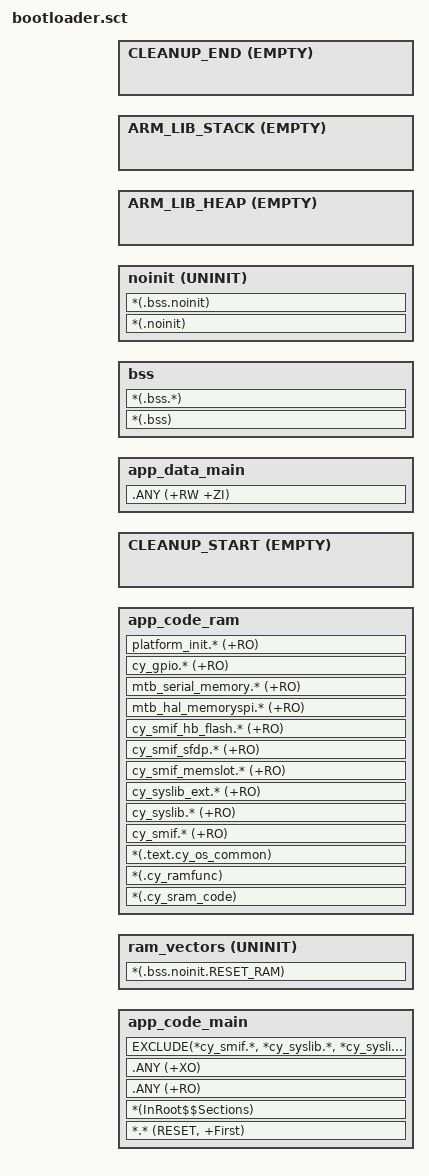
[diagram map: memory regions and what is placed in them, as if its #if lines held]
#! armclang -E --target=arm-arm-none-eabi -mcpu=cortex-m33 -xc
; command above MUST be in first line (no comment above!)
/***************************************************************************/ 






































/* Include the device memory definitions generated by the Device Configurator */
#include "../../config/GeneratedSource/cymem_armlink_CM33_0_S.sct"

/* Define the stack size for the application */
/* To set stack size in application add makefile ldflags: --predefine="-DAPP_MSP_STACK_SIZE=<CUSTOM_VALUE>" */
#ifdef APP_MSP_STACK_SIZE
#define __STACK_SIZE    APP_MSP_STACK_SIZE
#else
#define __STACK_SIZE    0x00002000
#endif

/* User Stack & Heap boundary definition */
/* Place the top of the stack at the end of the m33s_data_S */
#define __STACK_TOP    (CYMEM_CM33_0_S_m33s_data_S_START + CYMEM_CM33_0_S_m33s_data_SIZE)
/* Position the beginning of the heap right after the noinit ER, ensuring an 8-byte alignment */
#define __HEAP_BASE    AlignExpr(ImageLimit(noinit), 8)
/* The heap extends to the stack */
#define __HEAP_SIZE    (__STACK_TOP - __STACK_SIZE - __HEAP_BASE)

/* Device definitions */
#define VECTORS_ALIGNMENT 0x400

/* The size of the MCU boot header area at the start of main code region */
#define MCUBOOT_HEADER_SIZE  0x400

/* The size of the signature trail area at the end of main code region */
#define SIGNATURE_TRAIL_SIZE 0x400


/* Serial Memory Interface block #0 memory #1, 16 MB */
/* Start address is offset by MCUBOOT_HEADER_SIZE to let the area free for the MCU boot header */
LR_XIP_PORT0 (CYMEM_CM33_0_S_bootloader_nvm_sel_S_START + MCUBOOT_HEADER_SIZE) (CYMEM_CM33_0_S_bootloader_nvm_SIZE - MCUBOOT_HEADER_SIZE - SIGNATURE_TRAIL_SIZE)
{
  /* The execution region is designated for the main secure (S) application code for the Cortex-M33 */
  /* Performance-sensitive or critical functions that need to be executed in sram are manually excluded */
  app_code_main (CYMEM_CM33_0_S_bootloader_nvm_sel_S_START + MCUBOOT_HEADER_SIZE) ALIGN VECTORS_ALIGNMENT (CYMEM_CM33_0_S_bootloader_nvm_SIZE - MCUBOOT_HEADER_SIZE)
  {
    *.* (RESET, +First)
    *(InRoot$$Sections)
    .ANY (+RO)
    .ANY (+XO)
    EXCLUDE(*cy_smif.*, *cy_syslib.*, *cy_syslib_ext.*, *cy_smif_memslot.*, *cy_smif_sfdp.*, *cy_smif_hb_flash.*, *mtb_hal_memoryspi.*, *mtb_serial_memory.*, *cy_gpio.*, *platform_init.* )
  }

  /* A region for the vector table */
  ram_vectors AlignExpr(CYMEM_CM33_0_S_m33s_data_S_START, VECTORS_ALIGNMENT) ALIGN VECTORS_ALIGNMENT UNINIT CYMEM_CM33_0_S_m33s_data_SIZE
  {
    *(.bss.noinit.RESET_RAM)
  }

  /* The execution region for performance-sensitive or critical functions that need to be executed in SRAM */
  app_code_ram AlignExpr(ImageLimit(ram_vectors), 8) ALIGN 8 CYMEM_CM33_0_S_m33s_data_SIZE
  {
    *(.cy_sram_code)
    *(.cy_ramfunc)
    *(.text.cy_os_common)
    cy_smif.* (+RO)
    cy_syslib.* (+RO)
    cy_syslib_ext.* (+RO)
    cy_smif_memslot.* (+RO)
    cy_smif_sfdp.* (+RO)
    cy_smif_hb_flash.* (+RO)
    mtb_hal_memoryspi.* (+RO)
    mtb_serial_memory.* (+RO)
    cy_gpio.* (+RO)
    platform_init.* (+RO)
  }

  /* This empty, zero long execution region is here to mark the start address of cleanup region */
  CLEANUP_START AlignExpr(ImageLimit(app_code_ram), 4) ALIGN 4 EMPTY 0x0 {}

  /* The execution region for initialized data memory */
  app_data_main AlignExpr(ImageLimit(app_code_ram), 4) ALIGN 4 CYMEM_CM33_0_S_m33s_data_SIZE
  {
    .ANY (+RW +ZI)
  }
}

/* SRAM, 1 MB */
/* Note. This load region must not contain any loadable data; only UNINIT or BSS execution regions are allowed */
LR_SRAM CYMEM_CM33_0_S_m33s_data_S_START CYMEM_CM33_0_S_m33s_data_SIZE
{

  /* A section for non-initialized data memory */
  bss AlignExpr(ImageLimit(app_data_main), 8) ALIGN 8 (CYMEM_CM33_0_S_m33s_data_SIZE - AlignExpr(ImageLength(ram_vectors), VECTORS_ALIGNMENT) - AlignExpr(ImageLength(app_data_main), 4))
  {
    *(.bss)
    *(.bss.*)
  }

  /* A region for variables that should not be initialized during the device startup */
  noinit AlignExpr(ImageLimit(bss), 4) ALIGN 4 UNINIT (CYMEM_CM33_0_S_m33s_data_SIZE - AlignExpr(ImageLength(ram_vectors), VECTORS_ALIGNMENT) - AlignExpr(ImageLength(app_data_main), 4) - AlignExpr(ImageLength(bss), 4))
  {
    *(.noinit)
    *(.bss.noinit)
  }

  /* A region for the heap memory */
  ARM_LIB_HEAP __HEAP_BASE EMPTY __HEAP_SIZE
  {
  }

  /* A region for stack */
  ARM_LIB_STACK __STACK_TOP EMPTY -__STACK_SIZE
  {
  }

  /* This empty, zero long execution region is here to mark the end address of cleanup region */
  CLEANUP_END __STACK_TOP EMPTY 0x0 {}
}
